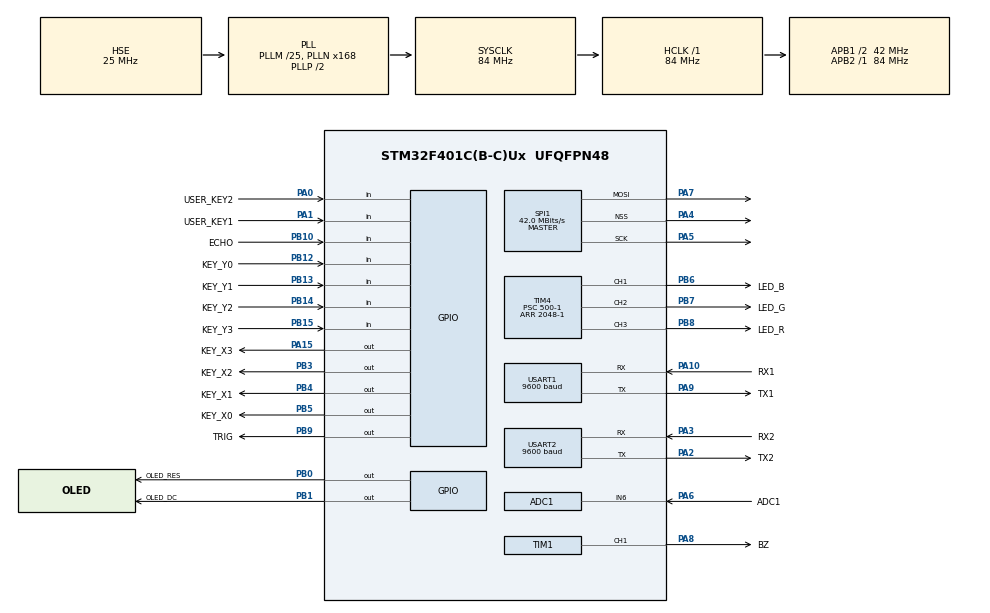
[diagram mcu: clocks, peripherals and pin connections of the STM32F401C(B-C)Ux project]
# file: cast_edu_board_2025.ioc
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ADC1.Channel-0\#ChannelRegularConversion=ADC_CHANNEL_6
ADC1.ContinuousConvMode=ENABLE
ADC1.DMAContinuousRequests=ENABLE
ADC1.ExternalTrigConv=ADC_SOFTWARE_START
ADC1.InjNumberOfConversion=0
ADC1.NbrOfConversionFlag=1
ADC1.Rank-0\#ChannelRegularConversion=1
ADC1.SamplingTime-0\#ChannelRegularConversion=ADC_SAMPLETIME_3CYCLES
ADC1.master=1
Dma.ADC1.0.Direction=DMA_PERIPH_TO_MEMORY
Dma.ADC1.0.FIFOMode=DMA_FIFOMODE_DISABLE
Dma.ADC1.0.Instance=DMA2_Stream0
Dma.ADC1.0.MemDataAlignment=DMA_MDATAALIGN_HALFWORD
Dma.ADC1.0.MemInc=DMA_MINC_ENABLE
Dma.ADC1.0.Mode=DMA_CIRCULAR
Dma.ADC1.0.PeriphDataAlignment=DMA_PDATAALIGN_HALFWORD
Dma.ADC1.0.PeriphInc=DMA_PINC_DISABLE
Dma.ADC1.0.Priority=DMA_PRIORITY_LOW
Dma.Request0=ADC1
Mcu.Family=STM32F4
Mcu.Name=STM32F401C(B-C)Ux
Mcu.Package=UFQFPN48
NVIC.DMA2_Stream0_IRQn=true\:0\:0\:false\:false\:true\:false\:true\:true
NVIC.PriorityGroup=NVIC_PRIORITYGROUP_4
NVIC.TIM1_BRK_TIM9_IRQn=true\:0\:0\:false\:false\:true\:true\:true\:true
NVIC.TIM2_IRQn=true\:0\:0\:false\:false\:true\:true\:true\:true
NVIC.TIM3_IRQn=true\:0\:0\:false\:false\:true\:true\:true\:true
NVIC.TIM4_IRQn=true\:0\:0\:false\:false\:true\:true\:true\:true
NVIC.TIM5_IRQn=true\:0\:0\:false\:false\:true\:true\:true\:true
NVIC.USART1_IRQn=true\:0\:0\:false\:false\:true\:true\:true\:true
NVIC.USART2_IRQn=true\:0\:0\:false\:false\:true\:true\:true\:true
PA0-WKUP.GPIO_Label=USER_KEY2
PA0-WKUP.GPIO_PuPd=GPIO_PULLUP
PA0-WKUP.Signal=GPIO_Input
PA1.GPIO_Label=USER_KEY1
PA1.GPIO_PuPd=GPIO_PULLUP
PA1.Signal=GPIO_Input
PA10.GPIO_Label=RX1
PA10.Mode=Asynchronous
PA10.Signal=USART1_RX
PA13.Mode=Serial_Wire
PA13.Signal=SYS_JTMS-SWDIO
PA14.Mode=Serial_Wire
PA14.Signal=SYS_JTCK-SWCLK
PA15.GPIO_Label=KEY_X3
PA15.GPIO_PuPd=GPIO_PULLDOWN
PA15.Signal=GPIO_Output
PA2.GPIO_Label=TX2
PA2.Mode=Asynchronous
PA2.Signal=USART2_TX
PA3.GPIO_Label=RX2
PA3.Mode=Asynchronous
PA3.Signal=USART2_RX
PA4.Mode=NSS_Signal_Hard_Output
PA4.Signal=SPI1_NSS
PA5.Mode=TX_Only_Simplex_Unidirect_Master
PA5.Signal=SPI1_SCK
PA6.GPIO_Label=ADC1
PA6.Signal=ADCx_IN6
PA7.Mode=TX_Only_Simplex_Unidirect_Master
PA7.Signal=SPI1_MOSI
PA8.GPIO_Label=BZ
PA8.Signal=S_TIM1_CH1
PA9.GPIO_Label=TX1
PA9.Mode=Asynchronous
PA9.Signal=USART1_TX
PB0.GPIO_Label=OLED_RES
PB0.GPIO_PuPd=GPIO_NOPULL
PB0.PinState=GPIO_PIN_SET
PB0.Signal=GPIO_Output
PB1.GPIO_Label=OLED_DC
PB1.GPIO_PuPd=GPIO_NOPULL
PB1.Signal=GPIO_Output
PB10.GPIO_Label=ECHO
PB10.Signal=GPIO_Input
PB12.GPIO_Label=KEY_Y0
PB12.GPIO_PuPd=GPIO_PULLDOWN
PB12.Signal=GPIO_Input
PB13.GPIO_Label=KEY_Y1
PB13.GPIO_PuPd=GPIO_PULLDOWN
PB13.Signal=GPIO_Input
PB14.GPIO_Label=KEY_Y2
PB14.GPIO_PuPd=GPIO_PULLDOWN
PB14.Signal=GPIO_Input
PB15.GPIO_Label=KEY_Y3
PB15.GPIO_PuPd=GPIO_PULLDOWN
PB15.Signal=GPIO_Input
PB3.GPIO_Label=KEY_X2
PB3.GPIO_PuPd=GPIO_PULLDOWN
PB3.Signal=GPIO_Output
PB4.GPIO_Label=KEY_X1
PB4.GPIO_PuPd=GPIO_PULLDOWN
PB4.Signal=GPIO_Output
PB5.GPIO_Label=KEY_X0
PB5.GPIO_PuPd=GPIO_PULLDOWN
PB5.Signal=GPIO_Output
PB6.GPIO_Label=LED_B
PB6.Signal=S_TIM4_CH1
PB7.GPIO_Label=LED_G
PB7.Signal=S_TIM4_CH2
PB8.GPIO_Label=LED_R
PB8.Signal=S_TIM4_CH3
PB9.GPIO_Label=TRIG
PB9.Signal=GPIO_Output
PH0\ -\ OSC_IN.Mode=HSE-External-Oscillator
PH0\ -\ OSC_IN.Signal=RCC_OSC_IN
PH1\ -\ OSC_OUT.Mode=HSE-External-Oscillator
PH1\ -\ OSC_OUT.Signal=RCC_OSC_OUT
ProjectManager.HeapSize=0x200
ProjectManager.StackSize=0x400
ProjectManager.TargetToolchain=STM32CubeIDE
RCC.48MHZClocksFreq_Value=42000000
RCC.AHBFreq_Value=84000000
RCC.APB1CLKDivider=RCC_HCLK_DIV2
RCC.APB1Freq_Value=42000000
RCC.APB1TimFreq_Value=84000000
RCC.APB2Freq_Value=84000000
RCC.APB2TimFreq_Value=84000000
RCC.CortexFreq_Value=84000000
RCC.HCLKFreq_Value=84000000
RCC.HSE_VALUE=25000000
RCC.HSI_VALUE=16000000
RCC.LSE_VALUE=32768
RCC.PLLM=25
RCC.PLLN=168
RCC.PLLSourceVirtual=RCC_PLLSOURCE_HSE
RCC.SYSCLKFreq_VALUE=84000000
RCC.SYSCLKSource=RCC_SYSCLKSOURCE_PLLCLK
RCC.VCOOutputFreq_Value=168000000
SH.ADCx_IN6.0=ADC1_IN6,IN6
SH.S_TIM1_CH1.0=TIM1_CH1,PWM Generation1 CH1
SH.S_TIM4_CH1.0=TIM4_CH1,PWM Generation1 CH1
SH.S_TIM4_CH2.0=TIM4_CH2,PWM Generation2 CH2
SH.S_TIM4_CH3.0=TIM4_CH3,PWM Generation3 CH3
SPI1.CalculateBaudRate=42.0 MBits/s
SPI1.Direction=SPI_DIRECTION_2LINES
SPI1.Mode=SPI_MODE_MASTER
SPI1.VirtualNSS=VM_NSSHARD
SPI1.VirtualType=VM_MASTER
TIM1.Channel-PWM\ Generation1\ CH1=TIM_CHANNEL_1
TIM1.Period=100-1
TIM1.Prescaler=84-1
TIM2.Period=1000-1
TIM2.Prescaler=8400-1
TIM2.TIM_MasterOutputTrigger=TIM_TRGO_UPDATE
TIM3.Period=100-1
TIM3.Prescaler=84-1
TIM4.Channel-PWM\ Generation1\ CH1=TIM_CHANNEL_1
TIM4.Channel-PWM\ Generation2\ CH2=TIM_CHANNEL_2
TIM4.Channel-PWM\ Generation3\ CH3=TIM_CHANNEL_3
TIM4.OCPolarity_1=TIM_OCPOLARITY_LOW
TIM4.OCPolarity_2=TIM_OCPOLARITY_LOW
TIM4.OCPolarity_3=TIM_OCPOLARITY_LOW
TIM4.Period=2048-1
TIM4.Prescaler=500-1
TIM4.Pulse-PWM\ Generation1\ CH1=0
TIM4.Pulse-PWM\ Generation2\ CH2=0
TIM4.Pulse-PWM\ Generation3\ CH3=0
TIM5.Period=10000-1
TIM5.Prescaler=8400-1
TIM5.TIM_MasterOutputTrigger=TIM_TRGO_UPDATE
TIM9.Period=25000-1
TIM9.Prescaler=8400-1
USART1.BaudRate=9600
USART1.VirtualMode=VM_ASYNC
USART2.BaudRate=9600
USART2.VirtualMode=VM_ASYNC
VP_TIM1_VS_ClockSourceINT.Mode=Internal
VP_TIM2_VS_ClockSourceINT.Mode=Internal
VP_TIM3_VS_ClockSourceINT.Mode=Internal
VP_TIM4_VS_ClockSourceINT.Mode=Internal
VP_TIM5_VS_ClockSourceINT.Mode=Internal
VP_TIM9_VS_ClockSourceINT.Mode=Internal
board=custom

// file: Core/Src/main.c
/* USER CODE BEGIN Header */
/**
  ******************************************************************************
  * @file           : main.c
  * @brief          : Main program body
  ******************************************************************************
  * @attention
  *
  * Copyright (c) 2023 STMicroelectronics.
  * All rights reserved.
  *
  * This software is licensed under terms that can be found in the LICENSE file
  * in the root directory of this software component.
  * If no LICENSE file comes with this software, it is provided AS-IS.
  *
  ******************************************************************************
  */
/* USER CODE END Header */
#include "main.h"
#include "adc.h"
#include "dma.h"
#include "spi.h"
#include "tim.h"
#include "usart.h"
#include "gpio.h"

/* USER CODE BEGIN Includes */
#include <app_main.h>
/* USER CODE END Includes */

void SystemClock_Config(void);

int main(void)
{

  /* USER CODE BEGIN 1 */
  app_pre_init();
  /* USER CODE END 1 */

  /* MCU Configuration--------------------------------------------------------*/

  /* Reset of all peripherals, Initializes the Flash interface and the Systick. */
  HAL_Init();

  /* USER CODE BEGIN Init */
  app_init();
  /* USER CODE END Init */

  /* Configure the system clock */
  SystemClock_Config();

  /* USER CODE BEGIN SysInit */
  app_sys_init();
  /* USER CODE END SysInit */

  /* Initialize all configured peripherals */
  MX_GPIO_Init();
  MX_DMA_Init();
  MX_SPI1_Init();
  MX_TIM1_Init();
  MX_TIM4_Init();
  MX_TIM3_Init();
  MX_USART1_UART_Init();
  MX_ADC1_Init();
  MX_USART2_UART_Init();
  MX_TIM5_Init();
  MX_TIM9_Init();
  MX_TIM2_Init();
  /* USER CODE BEGIN 2 */
  app_main();
  /* USER CODE END 2 */

  /* Infinite loop */
  while (1)
  {

  }
}

void SystemClock_Config(void)
{
  RCC_OscInitTypeDef RCC_OscInitStruct = {0};
  RCC_ClkInitTypeDef RCC_ClkInitStruct = {0};

  /** Configure the main internal regulator output voltage
  */
  __HAL_RCC_PWR_CLK_ENABLE();
  __HAL_PWR_VOLTAGESCALING_CONFIG(PWR_REGULATOR_VOLTAGE_SCALE2);

  /** Initializes the RCC Oscillators according to the specified parameters
  * in the RCC_OscInitTypeDef structure.
  */
  RCC_OscInitStruct.OscillatorType = RCC_OSCILLATORTYPE_HSE;
  RCC_OscInitStruct.HSEState = RCC_HSE_ON;
  RCC_OscInitStruct.PLL.PLLState = RCC_PLL_ON;
  RCC_OscInitStruct.PLL.PLLSource = RCC_PLLSOURCE_HSE;
  RCC_OscInitStruct.PLL.PLLM = 25;
  RCC_OscInitStruct.PLL.PLLN = 168;
  RCC_OscInitStruct.PLL.PLLP = RCC_PLLP_DIV2;
  RCC_OscInitStruct.PLL.PLLQ = 4;
  if (HAL_RCC_OscConfig(&RCC_OscInitStruct) != HAL_OK)
  {
    Error_Handler();
  }

  /** Initializes the CPU, AHB and APB buses clocks
  */
  RCC_ClkInitStruct.ClockType = RCC_CLOCKTYPE_HCLK|RCC_CLOCKTYPE_SYSCLK
                              |RCC_CLOCKTYPE_PCLK1|RCC_CLOCKTYPE_PCLK2;
  RCC_ClkInitStruct.SYSCLKSource = RCC_SYSCLKSOURCE_PLLCLK;
  RCC_ClkInitStruct.AHBCLKDivider = RCC_SYSCLK_DIV1;
  RCC_ClkInitStruct.APB1CLKDivider = RCC_HCLK_DIV2;
  RCC_ClkInitStruct.APB2CLKDivider = RCC_HCLK_DIV1;

  if (HAL_RCC_ClockConfig(&RCC_ClkInitStruct, FLASH_LATENCY_2) != HAL_OK)
  {
    Error_Handler();
  }
}

void Error_Handler(void)
{
  __disable_irq();
  while (1)
  {
  }
}
